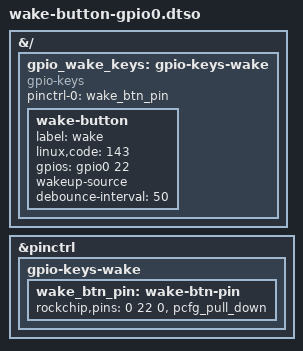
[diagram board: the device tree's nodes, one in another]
// SPDX-License-Identifier: BSD-3-Clause
/*
 * Wake push-button on Radxa CM3 (RK3566) / CM4IO 40-pin header PIN 33.
 *
 * PIN 33 = BCM GPIO13 (schematic net) = Rockchip GPIO0_C6 = gpiochip0 line 22
 * (confirmed via /sys/kernel/debug/gpio: "gpio-22 (PIN_33)"). GPIO0 is the
 * PMU/always-on bank — the ONLY GPIO bank kept powered in deep suspend (mem/STR)
 * on RK3566, so it can actually wake the SoC. A button on GPIO1..4 would NOT wake.
 * (Earlier this was on phys pin 13 = GPIO0_B7 = BCM27/"D27" — wrong pin; the
 * schematic's "GPIO13" is BCM numbering = physical pin 33.)
 *
 * IGN_SENSE wiring (per HAT schematic, KiCad chat 2026-08-16): pin 33 goes HIGH when
 * ignition is sensed, LOW when off. So: ACTIVE_HIGH + internal pull-DOWN (idles low =
 * stays asleep / fail-safe if the line floats when ign is off). The active-high flag is
 * what sets the wake trigger to the ign-ON (rising) edge — gpio-keys infers it. KEY_WAKEUP
 * (143) not KEY_POWER so a press while awake isn't treated by logind as shutdown.
 * OPEN ITEMS: (a) this dtbo does the WAKE half only — suspend on ign-OFF needs a userspace
 * watcher (`systemctl suspend` on the falling edge), level-aware at boot [[project_cm3_suspend]].
 * (b) Only pin 13/GPIO0_B7 is PROVEN to wake from deep STR; pin 33/GPIO0_C6 is UNVERIFIED —
 * confirm it actually wakes before trusting this. (c) Verify the real level through the HAT
 * Block A front-end (it may invert); pull-down is harmless if the HAT actively drives low.
 *
 * Stack this with the CAN + DSI overlays when pre-merging into the base DTB:
 *   fdtoverlay -i base.orig -o both.dtb mcp2515-2ch-hatplus.dtbo \
 *              waveshare-12in3-dsi1.dtbo wake-button-gpio0.dtbo
 * (U-Boot fdtoverlays apply traps into rescue on this board — always pre-merge.)
 */
/dts-v1/;
/plugin/;

&{/} {
	gpio_wake_keys: gpio-keys-wake {
		compatible = "gpio-keys";
		pinctrl-names = "default";
		pinctrl-0 = <&wake_btn_pin>;

		wake-button {
			label = "wake";
			linux,code = <143>;		/* KEY_WAKEUP */
			gpios = <&gpio0 22 0>;		/* GPIO0_C6 (hdr pin 33), GPIO_ACTIVE_HIGH (IGN_SENSE high=on) */
			wakeup-source;
			debounce-interval = <50>;
		};
	};
};

&pinctrl {
	gpio-keys-wake {
		wake_btn_pin: wake-btn-pin {
			/* bank 0, RK_PC6 (=22), func GPIO (0), internal pull-DOWN (idle low = asleep).
			   pcfg_pull_down is a base-DTB symbol (resolved by fdtoverlay). */
			rockchip,pins = <0 22 0 &pcfg_pull_down>;
		};
	};
};
